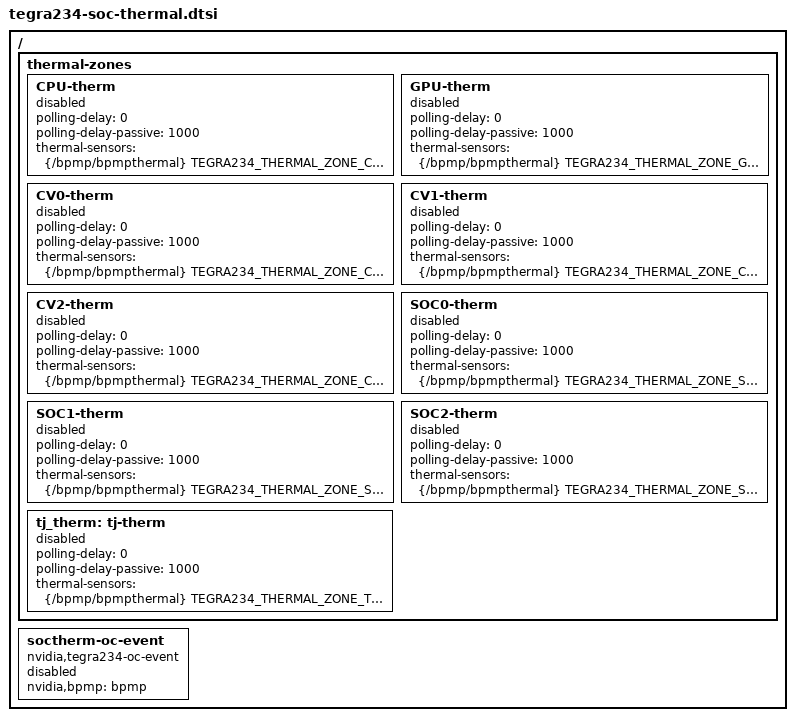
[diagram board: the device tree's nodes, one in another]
/*
 * Copyright (c) 2017-2020, NVIDIA CORPORATION.  All rights reserved.
 *
 * This program is free software; you can redistribute it and/or modify it
 * under the terms and conditions of the GNU General Public License,
 * version 2, as published by the Free Software Foundation.
 *
 * This program is distributed in the hope it will be useful, but WITHOUT
 * ANY WARRANTY; without even the implied warranty of MERCHANTABILITY or
 * FITNESS FOR A PARTICULAR PURPOSE.  See the GNU General Public License for
 * more details.
 *
 * You should have received a copy of the GNU General Public License
 * along with this program.  If not, see <http://www.gnu.org/licenses/>.
 */
#include <dt-bindings/thermal/tegra234-thermal.h>

/ {
	thermal-zones {
		CPU-therm {
			polling-delay = <0>;
			polling-delay-passive = <1000>;
			thermal-sensors = <&{/bpmp/bpmpthermal} TEGRA234_THERMAL_ZONE_CPU>;
			status = "disabled";
		};

		GPU-therm {
			polling-delay = <0>;
			polling-delay-passive = <1000>;
			thermal-sensors = <&{/bpmp/bpmpthermal} TEGRA234_THERMAL_ZONE_GPU>;
			status = "disabled";
		};

		CV0-therm {
			polling-delay = <0>;
			polling-delay-passive = <1000>;
			thermal-sensors = <&{/bpmp/bpmpthermal} TEGRA234_THERMAL_ZONE_CV0>;
			status = "disabled";
		};

		CV1-therm {
			polling-delay = <0>;
			polling-delay-passive = <1000>;
			thermal-sensors = <&{/bpmp/bpmpthermal} TEGRA234_THERMAL_ZONE_CV1>;
			status = "disabled";
		};

		CV2-therm {
			polling-delay = <0>;
			polling-delay-passive = <1000>;
			thermal-sensors = <&{/bpmp/bpmpthermal} TEGRA234_THERMAL_ZONE_CV2>;
			status = "disabled";
		};

		SOC0-therm {
			polling-delay = <0>;
			polling-delay-passive = <1000>;
			thermal-sensors = <&{/bpmp/bpmpthermal} TEGRA234_THERMAL_ZONE_SOC0>;
			status = "disabled";
		};

		SOC1-therm {
			polling-delay = <0>;
			polling-delay-passive = <1000>;
			thermal-sensors = <&{/bpmp/bpmpthermal} TEGRA234_THERMAL_ZONE_SOC1>;
			status = "disabled";
		};

		SOC2-therm {
			polling-delay = <0>;
			polling-delay-passive = <1000>;
			thermal-sensors = <&{/bpmp/bpmpthermal} TEGRA234_THERMAL_ZONE_SOC2>;
			status = "disabled";
		};

		tj_therm: tj-therm {
			polling-delay = <0>;
			polling-delay-passive = <1000>;
			thermal-sensors = <&{/bpmp/bpmpthermal} TEGRA234_THERMAL_ZONE_TJ_MAX>;
			status = "disabled";
		};
	};

	soctherm-oc-event {
		compatible = "nvidia,tegra234-oc-event";
		nvidia,bpmp = <&bpmp>;
		status = "disabled";
	};
};
